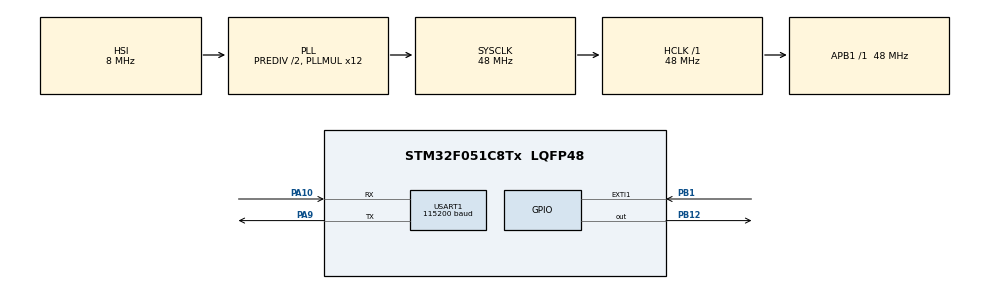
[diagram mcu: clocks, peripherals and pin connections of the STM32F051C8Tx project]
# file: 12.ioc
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Dma.Request0=USART1_RX
Dma.Request1=USART1_TX
Dma.USART1_RX.0.Direction=DMA_PERIPH_TO_MEMORY
Dma.USART1_RX.0.Instance=DMA1_Channel3
Dma.USART1_RX.0.MemDataAlignment=DMA_MDATAALIGN_BYTE
Dma.USART1_RX.0.MemInc=DMA_MINC_ENABLE
Dma.USART1_RX.0.Mode=DMA_NORMAL
Dma.USART1_RX.0.PeriphDataAlignment=DMA_PDATAALIGN_BYTE
Dma.USART1_RX.0.PeriphInc=DMA_PINC_DISABLE
Dma.USART1_RX.0.Priority=DMA_PRIORITY_HIGH
Dma.USART1_TX.1.Direction=DMA_MEMORY_TO_PERIPH
Dma.USART1_TX.1.Instance=DMA1_Channel2
Dma.USART1_TX.1.MemDataAlignment=DMA_MDATAALIGN_BYTE
Dma.USART1_TX.1.MemInc=DMA_MINC_ENABLE
Dma.USART1_TX.1.Mode=DMA_NORMAL
Dma.USART1_TX.1.PeriphDataAlignment=DMA_PDATAALIGN_BYTE
Dma.USART1_TX.1.PeriphInc=DMA_PINC_DISABLE
Dma.USART1_TX.1.Priority=DMA_PRIORITY_LOW
Mcu.Family=STM32F0
Mcu.Name=STM32F051C8Tx
Mcu.Package=LQFP48
NVIC.DMA1_Channel2_3_IRQn=true\:0\:0\:false\:false\:true\:false
NVIC.USART1_IRQn=true\:2\:0\:true\:false\:true\:true
PA10.Mode=Asynchronous
PA10.Signal=USART1_RX
PA13.Mode=Serial_Wire
PA13.Signal=SYS_SWDIO
PA14.Mode=Serial_Wire
PA14.Signal=SYS_SWCLK
PA9.Mode=Asynchronous
PA9.Signal=USART1_TX
PB1.Signal=GPXTI1
PB12.Signal=GPIO_Output
ProjectManager.HeapSize=0x200
ProjectManager.StackSize=0x400
ProjectManager.TargetToolchain=MDK-ARM V5
RCC.AHBFreq_Value=48000000
RCC.APB1Freq_Value=48000000
RCC.APB1TimFreq_Value=48000000
RCC.HCLKFreq_Value=48000000
RCC.PLLDivider=RCC_PREDIV_DIV2
RCC.PLLMUL=RCC_PLL_MUL12
RCC.SYSCLKFreq_VALUE=48000000
RCC.SYSCLKSource=RCC_SYSCLKSOURCE_PLLCLK
STMicroelectronics.X-CUBE-MEMS1.5.2.1.ApplicationCcDeviceJjApplication=IKS01A2IiLSM6DSLIiWakeUp
STMicroelectronics.X-CUBE-MEMS1.5.2.1.BoardOoComponentJjMEMS.apiComponent0=Board Extension\:IKS01A2
STMicroelectronics.X-CUBE-MEMS1.5.2.1.BoardOoComponentJjMEMS.apiDoc0=Documentation/X_CUBE_MEMS1.chm
STMicroelectronics.X-CUBE-MEMS1.5.2.1.BoardOoComponentJjMEMS.cmp_version0=5.2.1
STMicroelectronics.X-CUBE-MEMS1.5.2.1.BoardOoComponentJjMEMS.component0=Board Component
STMicroelectronics.X-CUBE-MEMS1.5.2.1.BoardOoComponentJjMEMS.description0=MEMS library for custom boards,LSM6DSL component driver
STMicroelectronics.X-CUBE-MEMS1.5.2.1.BoardOoComponentJjMEMS.diagnostic0=This component should operate correctly.
STMicroelectronics.X-CUBE-MEMS1.5.2.1.BoardOoComponentJjMEMS.documentation0=Documentation/STMicroelectronics.X-CUBE-MEMS1_GettingStarted.pdf
STMicroelectronics.X-CUBE-MEMS1.5.2.1.BoardOoComponentJjMEMS.group0=AccGyr
STMicroelectronics.X-CUBE-MEMS1.5.2.1.BoardOoComponentJjMEMS.paramName0=MEMSCcBoardOoComponentJjAccGyrJjLSM6DSL
STMicroelectronics.X-CUBE-MEMS1.5.2.1.BoardOoComponentJjMEMS.sevirity0=none
STMicroelectronics.X-CUBE-MEMS1.5.2.1.BoardOoComponentJjMEMS.sub-group0=LSM6DSL
STMicroelectronics.X-CUBE-MEMS1.5.2.1.BoardOoComponentJjMEMS.variant0=SPI
STMicroelectronics.X-CUBE-MEMS1.5.2.1.BoardOoComponentJjMEMS_apiSize=1
STMicroelectronics.X-CUBE-MEMS1.5.2.1.BoardOoComponentJjMEMS_bundle=MEMS
STMicroelectronics.X-CUBE-MEMS1.5.2.1.BoardOoComponentJjMEMS_class=BoardOoComponent
STMicroelectronics.X-CUBE-MEMS1.5.2.1.BoardOoComponentJjMEMS_name=X-CUBE-MEMS1
STMicroelectronics.X-CUBE-MEMS1.5.2.1.BoardOoComponentJjMEMS_size=1
STMicroelectronics.X-CUBE-MEMS1.5.2.1.BoardOoComponentJjMEMS_vendor=STMicroelectronics
STMicroelectronics.X-CUBE-MEMS1.5.2.1.BoardOoComponentJjMEMS_version=5.2.1
STMicroelectronics.X-CUBE-MEMS1.5.2.1.DeviceJjApplication.apiComponent0=Board Extension\:IKS01A2
STMicroelectronics.X-CUBE-MEMS1.5.2.1.DeviceJjApplication.apiDoc0=Documentation/X_CUBE_MEMS1.chm
STMicroelectronics.X-CUBE-MEMS1.5.2.1.DeviceJjApplication.cmp_version0=5.2.1
STMicroelectronics.X-CUBE-MEMS1.5.2.1.DeviceJjApplication.component0=Device
STMicroelectronics.X-CUBE-MEMS1.5.2.1.DeviceJjApplication.description0=MEMS library applications,LSM6DSL Wake-Up Detection sample application for X-NUCLEO-IKS01A2
STMicroelectronics.X-CUBE-MEMS1.5.2.1.DeviceJjApplication.diagnostic0=This component requires one or more component from the same SW pack to operate correctly
STMicroelectronics.X-CUBE-MEMS1.5.2.1.DeviceJjApplication.documentation0=Documentation/STMicroelectronics.X-CUBE-MEMS1_GettingStarted.pdf
STMicroelectronics.X-CUBE-MEMS1.5.2.1.DeviceJjApplication.group0=Application
STMicroelectronics.X-CUBE-MEMS1.5.2.1.DeviceJjApplication.paramName0=ApplicationCcDeviceJjApplication
STMicroelectronics.X-CUBE-MEMS1.5.2.1.DeviceJjApplication.sevirity0=minor
STMicroelectronics.X-CUBE-MEMS1.5.2.1.DeviceJjApplication.variant0=IKS01A2_LSM6DSL_WakeUp
STMicroelectronics.X-CUBE-MEMS1.5.2.1.DeviceJjApplication_apiSize=1
STMicroelectronics.X-CUBE-MEMS1.5.2.1.DeviceJjApplication_bundle=Application
STMicroelectronics.X-CUBE-MEMS1.5.2.1.DeviceJjApplication_class=Device
STMicroelectronics.X-CUBE-MEMS1.5.2.1.DeviceJjApplication_name=X-CUBE-MEMS1
STMicroelectronics.X-CUBE-MEMS1.5.2.1.DeviceJjApplication_size=1
STMicroelectronics.X-CUBE-MEMS1.5.2.1.DeviceJjApplication_vendor=STMicroelectronics
STMicroelectronics.X-CUBE-MEMS1.5.2.1.DeviceJjApplication_version=5.2.1
STMicroelectronics.X-CUBE-MEMS1.5.2.1.MEMSCcBoardOoComponentJjAccGyrJjLSM6DSL=SPI
STMicroelectronics.X-CUBE-MEMS1.5.2.1_BoardOoComponentJjMEMS_RteComponent0=\#define LSM6DSL_ACCGYR_SPI
STMicroelectronics.X-CUBE-MEMS1.5.2.1_BoardOoComponentJjMEMS_RteComponentsize=1
STMicroelectronics.X-CUBE-MEMS1.5.2.1_BoardOoExtensionJjMEMS_RteComponentsize=0
STMicroelectronics.X-CUBE-MEMS1.5.2.1_BoardOoSupportJjSTM32CubeIiCustomIiBSPIiDrivers_RteComponentsize=0
STMicroelectronics.X-CUBE-MEMS1.5.2.1_DeviceJjApplication_RteComponent0=\#define IKS01A2_LSM6DSL_WAKEUP_DEMO
STMicroelectronics.X-CUBE-MEMS1.5.2.1_DeviceJjApplication_RteComponentsize=1
STMicroelectronics.X-CUBE-MEMS1.5.2.1_MwName0=Application
STMicroelectronics.X-CUBE-MEMS1.5.2.1_NumberOfMw=1
STMicroelectronics.X-CUBE-MEMS1.5.2.1_description=Drivers and sample applications for MEMS components
STMicroelectronics.X-CUBE-MEMS1.5.2.1_license=en.DM00367782.pdf
USART1.BaudRate=115200
USART1.VirtualMode-Asynchronous=VM_ASYNC
board=custom

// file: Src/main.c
/* USER CODE BEGIN Header */
/**
  ******************************************************************************
  * @file           : main.c
  * @brief          : Main program body
  ******************************************************************************
  * This notice applies to any and all portions of this file
  * that are not between comment pairs USER CODE BEGIN and
  * USER CODE END. Other portions of this file, whether
  * inserted by the user or by software development tools
  * are owned by their respective copyright owners.
  *
  * Copyright (c) 2019 STMicroelectronics International N.V.
  * All rights reserved.
  *
  * Redistribution and use in source and binary forms, with or without
  * modification, are permitted, provided that the following conditions are met:
  *
  * 1. Redistribution of source code must retain the above copyright notice,
  *    this list of conditions and the following disclaimer.
  * 2. Redistributions in binary form must reproduce the above copyright notice,
  *    this list of conditions and the following disclaimer in the documentation
  *    and/or other materials provided with the distribution.
  * 3. Neither the name of STMicroelectronics nor the names of other
  *    contributors to this software may be used to endorse or promote products
  *    derived from this software without specific written permission.
  * 4. This software, including modifications and/or derivative works of this
  *    software, must execute solely and exclusively on microcontroller or
  *    microprocessor devices manufactured by or for STMicroelectronics.
  * 5. Redistribution and use of this software other than as permitted under
  *    this license is void and will automatically terminate your rights under
  *    this license.
  *
  * THIS SOFTWARE IS PROVIDED BY STMICROELECTRONICS AND CONTRIBUTORS "AS IS"
  * AND ANY EXPRESS, IMPLIED OR STATUTORY WARRANTIES, INCLUDING, BUT NOT
  * LIMITED TO, THE IMPLIED WARRANTIES OF MERCHANTABILITY, FITNESS FOR A
  * PARTICULAR PURPOSE AND NON-INFRINGEMENT OF THIRD PARTY INTELLECTUAL PROPERTY
  * RIGHTS ARE DISCLAIMED TO THE FULLEST EXTENT PERMITTED BY LAW. IN NO EVENT
  * SHALL STMICROELECTRONICS OR CONTRIBUTORS BE LIABLE FOR ANY DIRECT, INDIRECT,
  * INCIDENTAL, SPECIAL, EXEMPLARY, OR CONSEQUENTIAL DAMAGES (INCLUDING, BUT NOT
  * LIMITED TO, PROCUREMENT OF SUBSTITUTE GOODS OR SERVICES; LOSS OF USE, DATA,
  * OR PROFITS; OR BUSINESS INTERRUPTION) HOWEVER CAUSED AND ON ANY THEORY OF
  * LIABILITY, WHETHER IN CONTRACT, STRICT LIABILITY, OR TORT (INCLUDING
  * NEGLIGENCE OR OTHERWISE) ARISING IN ANY WAY OUT OF THE USE OF THIS SOFTWARE,
  * EVEN IF ADVISED OF THE POSSIBILITY OF SUCH DAMAGE.
  *
  ******************************************************************************
  */
/* USER CODE END Header */

#include "main.h"

UART_HandleTypeDef huart1;
DMA_HandleTypeDef hdma_usart1_rx;
DMA_HandleTypeDef hdma_usart1_tx;

void SystemClock_Config(void);
static void MX_GPIO_Init(void);
static void MX_DMA_Init(void);
static void MX_USART1_UART_Init(void);

/* USER CODE BEGIN 0 */
int16_t ADC_Value_arr[12]={0};
/* USER CODE END 0 */

int main(void)
{

  /* MCU Configuration--------------------------------------------------------*/

  /* Reset of all peripherals, Initializes the Flash interface and the Systick. */
//  HAL_Init();

  /* Configure the system clock */
//  SystemClock_Config();

  /* Initialize all configured peripherals */
  MX_GPIO_Init();
  MX_DMA_Init();
  MX_USART1_UART_Init();

  /* Infinite loop */
  /* USER CODE BEGIN WHILE */
//  while (1)
//  {
    /* USER CODE END WHILE */

    /* USER CODE BEGIN 3 */
//  }

  /* USER CODE END 3 */
}

void SystemClock_Config(void)
{
  RCC_OscInitTypeDef RCC_OscInitStruct = {0};
  RCC_ClkInitTypeDef RCC_ClkInitStruct = {0};
  RCC_PeriphCLKInitTypeDef PeriphClkInit = {0};

  /**Initializes the CPU, AHB and APB busses clocks
  */
  RCC_OscInitStruct.OscillatorType = RCC_OSCILLATORTYPE_HSI;
  RCC_OscInitStruct.HSIState = RCC_HSI_ON;
  RCC_OscInitStruct.HSICalibrationValue = RCC_HSICALIBRATION_DEFAULT;
  RCC_OscInitStruct.PLL.PLLState = RCC_PLL_ON;
  RCC_OscInitStruct.PLL.PLLSource = RCC_PLLSOURCE_HSI;
  RCC_OscInitStruct.PLL.PLLMUL = RCC_PLL_MUL12;
  RCC_OscInitStruct.PLL.PREDIV = RCC_PREDIV_DIV2;
  if (HAL_RCC_OscConfig(&RCC_OscInitStruct) != HAL_OK)
  {
    Error_Handler();
  }
  /**Initializes the CPU, AHB and APB busses clocks
  */
  RCC_ClkInitStruct.ClockType = RCC_CLOCKTYPE_HCLK|RCC_CLOCKTYPE_SYSCLK
                              |RCC_CLOCKTYPE_PCLK1;
  RCC_ClkInitStruct.SYSCLKSource = RCC_SYSCLKSOURCE_PLLCLK;
  RCC_ClkInitStruct.AHBCLKDivider = RCC_SYSCLK_DIV1;
  RCC_ClkInitStruct.APB1CLKDivider = RCC_HCLK_DIV1;

  if (HAL_RCC_ClockConfig(&RCC_ClkInitStruct, FLASH_LATENCY_1) != HAL_OK)
  {
    Error_Handler();
  }
  PeriphClkInit.PeriphClockSelection = RCC_PERIPHCLK_USART1;
  PeriphClkInit.Usart1ClockSelection = RCC_USART1CLKSOURCE_PCLK1;
  if (HAL_RCCEx_PeriphCLKConfig(&PeriphClkInit) != HAL_OK)
  {
    Error_Handler();
  }
}

static void MX_USART1_UART_Init(void)
{

  huart1.Instance = USART1;
  huart1.Init.BaudRate = 115200;
  huart1.Init.WordLength = UART_WORDLENGTH_8B;
  huart1.Init.StopBits = UART_STOPBITS_1;
  huart1.Init.Parity = UART_PARITY_NONE;
  huart1.Init.Mode = UART_MODE_TX_RX;
  huart1.Init.HwFlowCtl = UART_HWCONTROL_NONE;
  huart1.Init.OverSampling = UART_OVERSAMPLING_16;
  huart1.Init.OneBitSampling = UART_ONE_BIT_SAMPLE_DISABLE;
  huart1.AdvancedInit.AdvFeatureInit = UART_ADVFEATURE_NO_INIT;
  if (HAL_UART_Init(&huart1) != HAL_OK)
  {
    Error_Handler();
  }

}

static void MX_DMA_Init(void)
{
  /* DMA controller clock enable */
  __HAL_RCC_DMA1_CLK_ENABLE();

  /* DMA interrupt init */
  /* DMA1_Channel2_3_IRQn interrupt configuration */
  HAL_NVIC_SetPriority(DMA1_Channel2_3_IRQn, 0, 0);
  HAL_NVIC_EnableIRQ(DMA1_Channel2_3_IRQn);

}

static void MX_GPIO_Init(void)
{
  GPIO_InitTypeDef GPIO_InitStruct = {0};

  /* GPIO Ports Clock Enable */
  __HAL_RCC_GPIOB_CLK_ENABLE();
  __HAL_RCC_GPIOA_CLK_ENABLE();

  /*Configure GPIO pin Output Level */
  HAL_GPIO_WritePin(GPIOB, GPIO_PIN_12, GPIO_PIN_RESET);

  /*Configure GPIO pin : PB1 */
  GPIO_InitStruct.Pin = GPIO_PIN_1;
  GPIO_InitStruct.Mode = GPIO_MODE_IT_RISING;
  GPIO_InitStruct.Pull = GPIO_NOPULL;
  HAL_GPIO_Init(GPIOB, &GPIO_InitStruct);

  /*Configure GPIO pin : PB12 */
  GPIO_InitStruct.Pin = GPIO_PIN_12;
  GPIO_InitStruct.Mode = GPIO_MODE_OUTPUT_PP;
  GPIO_InitStruct.Pull = GPIO_NOPULL;
  GPIO_InitStruct.Speed = GPIO_SPEED_FREQ_LOW;
  HAL_GPIO_Init(GPIOB, &GPIO_InitStruct);

}

void Error_Handler(void)
{
}

/************************ (C) COPYRIGHT STMicroelectronics *****END OF FILE****/
